# CY8C5868AXI_LP035 register map
File version: 0.1
CY8C58LP
Registers are 8-bit, read-write, no defined reset value unless marked. A register's access mark holds for its fields unless they carry their own. Offsets are from the block's base; lines under a group give offsets from that group; [hi:lo] are bit positions; {n}, {i} and the like mark numbered series; 'fields as' and 'values as' point back to an identical list; <NAME> marks a mode.

## Memory map
0x00000000 Timer_CH1
0x00000000 UART_2 — UART
0x00000000 Timer_CH2
0x00000000 Timer_CH3
0x00000000 Timer_Button
0x00000000 VDAC8
0x00000000 WaveDAC8_IDAC8
0x00000000 ADC — SAR ADC
0x00000000 Control_Reg
0x00000000 UART_1 — UART
0x00000000 PGA

## Timer_CH1
Base 0x00000000
0x40006409 Timer_CH1_COUNTER 16-bit — UDB.A0 - Current Down Counter Value
0x40006429 Timer_CH1_PERIOD 16-bit — UDB.D0 - Assigned Period
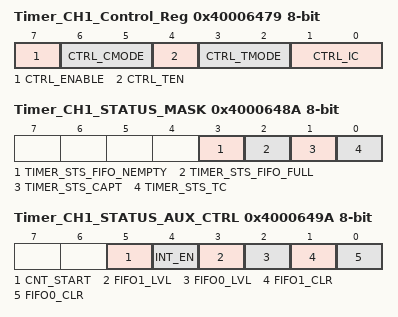
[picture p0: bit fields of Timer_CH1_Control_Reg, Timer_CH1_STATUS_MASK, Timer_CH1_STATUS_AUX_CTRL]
0x40006479 Timer_CH1_Control_Reg — UDB Control Register - Assigned Control Register Value
  [7] CTRL_ENABLE — Enable the Timer
  [6:5] CTRL_CMODE — Capture Mode
  [4] CTRL_TEN — Trigger Enable Bit
  [3:2] CTRL_TMODE — Trigger Mode
  [1:0] CTRL_IC — Interrupt Count
0x4000648A Timer_CH1_STATUS_MASK — UDB Status bits Interrupt Mask Enable Register
  [3] TIMER_STS_FIFO_NEMPTY ro — FIFO Empty status
  [2] TIMER_STS_FIFO_FULL ro — FIFO Full Status
  [1] TIMER_STS_CAPT ro — Enables the Interrupt on Capture
  [0] TIMER_STS_TC ro — Enables the Interrupt on TC
0x4000649A Timer_CH1_STATUS_AUX_CTRL — UDB Auxilliary Control Register
  [5] CNT_START — FIFO0 clear
    0=E_CNT_START0 (Disable counter); 1=E_CNT_START1 (Enable counter)
  [4] INT_EN
    0=E_INT_EN0 (Interrupt disabled); 1=E_INT_EN1 (Interrupt enabled)
  [3] FIFO1_LVL — FIFO level
    0=E_FIFO_LVL_0 (FIFO LVL: input mode: FIFO not full; output mode: FIFO not empty); 1=E_FIFO_LVL_1 (FIFO LVL: input mode: FIFO at least 1/2 empty; output mode: FIFO at least 1/2 full)
  [2] FIFO0_LVL — FIFO level
    values as FIFO1_LVL
  [1] FIFO1_CLR — FIFO1 clear
    0=E_FIFO_CLR_0 (Normal FIFO operation); 1=E_FIFO_CLR_1 (Clear FIFO state)
  [0] FIFO0_CLR — FIFO0 clear
    values as FIFO1_CLR

## UART_2 — UART
Base 0x00000000
0x4000642C RX_UART_2_RX_ADDRESS1 — RX Address1 Register
0x4000643C RX_UART_2_RX_ADDRESS2 — RX Address2 Register
0x4000644C RX_UART_2_RX_DATA — RX Data Register
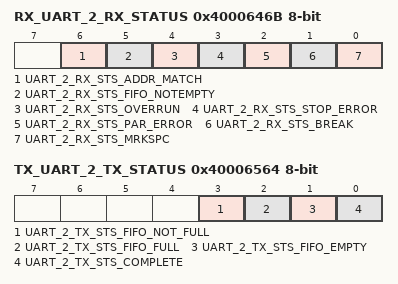
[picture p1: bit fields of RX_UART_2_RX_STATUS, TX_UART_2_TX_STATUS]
0x4000646B RX_UART_2_RX_STATUS — RX status register
  [6] UART_2_RX_STS_ADDR_MATCH ro, [5] UART_2_RX_STS_FIFO_NOTEMPTY ro, [4] UART_2_RX_STS_OVERRUN ro, [3] UART_2_RX_STS_STOP_ERROR ro, [2] UART_2_RX_STS_PAR_ERROR ro, [1] UART_2_RX_STS_BREAK ro, [0] UART_2_RX_STS_MRKSPC ro
0x40006544 TX_UART_2_TX_DATA — TX Data Register
0x40006564 TX_UART_2_TX_STATUS — TX status register
  [3] UART_2_TX_STS_FIFO_NOT_FULL ro, [2] UART_2_TX_STS_FIFO_FULL ro, [1] UART_2_TX_STS_FIFO_EMPTY ro, [0] UART_2_TX_STS_COMPLETE ro

## Timer_CH2
Base 0x00000000
0x4000650A Timer_CH2_COUNTER 16-bit — UDB.A0 - Current Down Counter Value
0x4000652A Timer_CH2_PERIOD 16-bit — UDB.D0 - Assigned Period
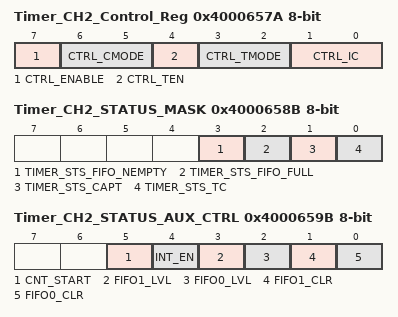
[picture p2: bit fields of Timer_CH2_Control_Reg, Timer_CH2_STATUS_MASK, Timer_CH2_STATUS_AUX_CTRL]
0x4000657A Timer_CH2_Control_Reg — UDB Control Register - Assigned Control Register Value
  [7] CTRL_ENABLE — Enable the Timer
  [6:5] CTRL_CMODE — Capture Mode
  [4] CTRL_TEN — Trigger Enable Bit
  [3:2] CTRL_TMODE — Trigger Mode
  [1:0] CTRL_IC — Interrupt Count
0x4000658B Timer_CH2_STATUS_MASK — UDB Status bits Interrupt Mask Enable Register
  [3] TIMER_STS_FIFO_NEMPTY ro — FIFO Empty status
  [2] TIMER_STS_FIFO_FULL ro — FIFO Full Status
  [1] TIMER_STS_CAPT ro — Enables the Interrupt on Capture
  [0] TIMER_STS_TC ro — Enables the Interrupt on TC
0x4000659B Timer_CH2_STATUS_AUX_CTRL — UDB Auxilliary Control Register
  [5] CNT_START — FIFO0 clear
    0=E_CNT_START0 (Disable counter); 1=E_CNT_START1 (Enable counter)
  [4] INT_EN
    0=E_INT_EN0 (Interrupt disabled); 1=E_INT_EN1 (Interrupt enabled)
  [3] FIFO1_LVL — FIFO level
    0=E_FIFO_LVL_0 (FIFO LVL: input mode: FIFO not full; output mode: FIFO not empty); 1=E_FIFO_LVL_1 (FIFO LVL: input mode: FIFO at least 1/2 empty; output mode: FIFO at least 1/2 full)
  [2] FIFO0_LVL — FIFO level
    values as FIFO1_LVL
  [1] FIFO1_CLR — FIFO1 clear
    0=E_FIFO_CLR_0 (Normal FIFO operation); 1=E_FIFO_CLR_1 (Clear FIFO state)
  [0] FIFO0_CLR — FIFO0 clear
    values as FIFO1_CLR
